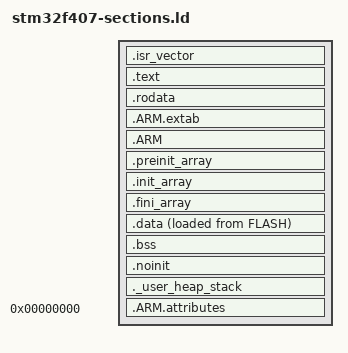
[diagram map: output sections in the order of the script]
/*
 * Output sections shared by every linker script in the tutorial (STM32F407,
 * and the STM32F103 one in dkx/). The including script defines the FLASH and
 * RAM regions and ENTRY.
 */

_min_heap_size  = 0x1000;
_min_stack_size = 0x1000;

SECTIONS
{
    /* The core reads its first two words from 0x08000000 after reset. */
    .isr_vector : {
        . = ALIGN(4);
        KEEP(*(.isr_vector))
        . = ALIGN(4);
    } > FLASH

    .text : {
        . = ALIGN(4);
        *(.text)
        *(.text*)
        *(.glue_7)
        *(.glue_7t)
        *(.eh_frame)

        KEEP(*(.init))
        KEEP(*(.fini))

        . = ALIGN(4);
        _etext = .;
    } > FLASH

    .rodata : {
        . = ALIGN(4);
        *(.rodata)
        *(.rodata*)
        . = ALIGN(4);
    } > FLASH

    .ARM.extab : {
        *(.ARM.extab* .gnu.linkonce.armextab.*)
    } > FLASH

    .ARM : {
        __exidx_start = .;
        *(.ARM.exidx*)
        __exidx_end = .;
    } > FLASH

    /* Constructor tables walked by __libc_init_array (C++ globals, attribute constructor). */
    .preinit_array : {
        PROVIDE_HIDDEN(__preinit_array_start = .);
        KEEP(*(.preinit_array*))
        PROVIDE_HIDDEN(__preinit_array_end = .);
    } > FLASH

    .init_array : {
        PROVIDE_HIDDEN(__init_array_start = .);
        KEEP(*(SORT(.init_array.*)))
        KEEP(*(.init_array*))
        PROVIDE_HIDDEN(__init_array_end = .);
    } > FLASH

    .fini_array : {
        PROVIDE_HIDDEN(__fini_array_start = .);
        KEEP(*(SORT(.fini_array.*)))
        KEEP(*(.fini_array*))
        PROVIDE_HIDDEN(__fini_array_end = .);
    } > FLASH

    /* Load address of .data inside FLASH; Reset_Handler copies from here. */
    _sidata = LOADADDR(.data);

    /* VMA in RAM, LMA in FLASH. */
    .data : {
        . = ALIGN(4);
        _sdata = .;
        *(.data)
        *(.data*)
        . = ALIGN(4);
        _edata = .;
    } > RAM AT> FLASH

    .bss (NOLOAD) : {
        . = ALIGN(4);
        _sbss = .;
        *(.bss)
        *(.bss*)
        *(COMMON)
        . = ALIGN(4);
        _ebss = .;
    } > RAM

    /* Neither copied nor zeroed by Reset_Handler: survives a reset (not a power cycle). */
    .noinit (NOLOAD) : {
        . = ALIGN(4);
        *(.noinit)
        *(.noinit*)
        . = ALIGN(4);
    } > RAM

    /* newlib's _sbrk grows the heap upward from `end`. */
    ._user_heap_stack (NOLOAD) : {
        . = ALIGN(8);
        PROVIDE(end = .);
        PROVIDE(_end = .);
        . = . + _min_heap_size;
        . = . + _min_stack_size;
        . = ALIGN(8);
    } > RAM

    .ARM.attributes 0 : { *(.ARM.attributes) }
}
